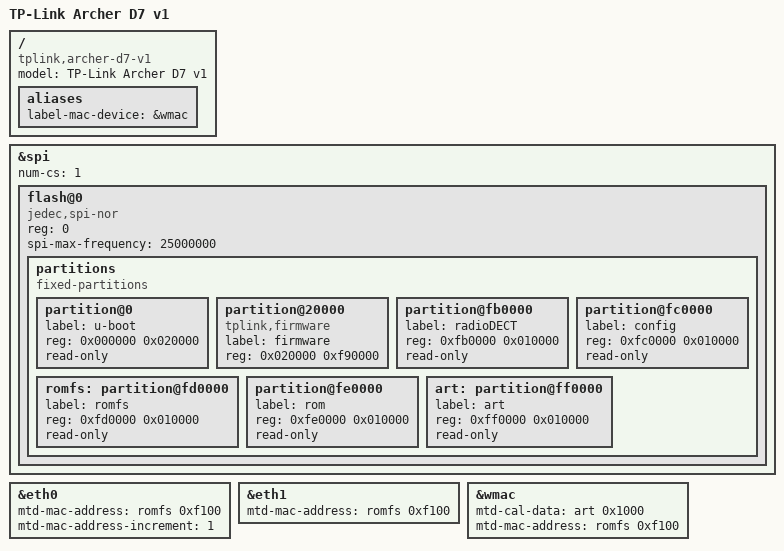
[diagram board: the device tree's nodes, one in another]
// SPDX-License-Identifier: GPL-2.0-or-later OR MIT
/dts-v1/;

#include "qca9558_tplink_archer-d7.dtsi"

/ {
	compatible = "tplink,archer-d7-v1", "qca,qca9558";
	model = "TP-Link Archer D7 v1";

	aliases {
		label-mac-device = &wmac;
	};
};

&spi {
	status = "okay";

	num-cs = <1>;

	flash@0 {
		compatible = "jedec,spi-nor";
		reg = <0>;
		spi-max-frequency = <25000000>;

		partitions {
			compatible = "fixed-partitions";
			#address-cells = <1>;
			#size-cells = <1>;

			partition@0 {
				label = "u-boot";
				reg = <0x000000 0x020000>;
				read-only;
			};

			partition@20000 {
				compatible = "tplink,firmware";
				label = "firmware";
				reg = <0x020000 0xf90000>;
			};

			partition@fb0000 {
				label = "radioDECT";
				reg = <0xfb0000 0x010000>;
				read-only;
			};

			partition@fc0000 {
				label = "config";
				reg = <0xfc0000 0x010000>;
				read-only;
			};

			romfs: partition@fd0000 {
				label = "romfs";
				reg = <0xfd0000 0x010000>;
				read-only;
			};

			partition@fe0000 {
				label = "rom";
				reg = <0xfe0000 0x010000>;
				read-only;
			};

			art: partition@ff0000 {
				label = "art";
				reg = <0xff0000 0x010000>;
				read-only;
			};
		};
	};
};

&eth0 {
	mtd-mac-address = <&romfs 0xf100>;
	mtd-mac-address-increment = <1>;
};

&eth1 {
	mtd-mac-address = <&romfs 0xf100>;
};

&wmac {
	mtd-cal-data = <&art 0x1000>;
	mtd-mac-address = <&romfs 0xf100>;
};
